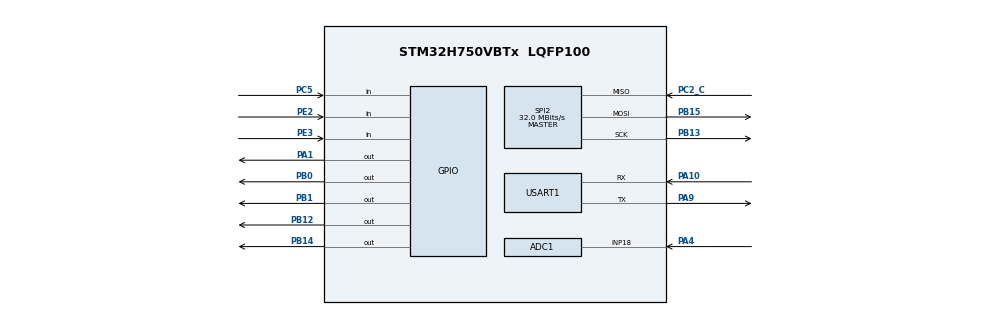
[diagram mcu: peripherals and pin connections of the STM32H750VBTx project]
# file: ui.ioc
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ADC1.Channel-3\#ChannelRegularConversion=ADC_CHANNEL_18
ADC1.ClockPrescaler=ADC_CLOCK_SYNC_PCLK_DIV4
ADC1.ContinuousConvMode=ENABLE
ADC1.ConversionDataManagement=ADC_CONVERSIONDATA_DMA_CIRCULAR
ADC1.NbrOfConversionFlag=1
ADC1.OffsetNumber-3\#ChannelRegularConversion=ADC_OFFSET_NONE
ADC1.OffsetSignedSaturation-3\#ChannelRegularConversion=DISABLE
ADC1.Rank-3\#ChannelRegularConversion=1
ADC1.Resolution=ADC_RESOLUTION_12B
ADC1.SamplingTime-3\#ChannelRegularConversion=ADC_SAMPLETIME_1CYCLE_5
ADC1.master=1
CORTEX_M7.default_mode_Activation=1
Dma.ADC1.3.Direction=DMA_PERIPH_TO_MEMORY
Dma.ADC1.3.EventEnable=DISABLE
Dma.ADC1.3.FIFOMode=DMA_FIFOMODE_DISABLE
Dma.ADC1.3.Instance=DMA1_Stream0
Dma.ADC1.3.MemDataAlignment=DMA_MDATAALIGN_WORD
Dma.ADC1.3.MemInc=DMA_MINC_ENABLE
Dma.ADC1.3.Mode=DMA_CIRCULAR
Dma.ADC1.3.PeriphDataAlignment=DMA_PDATAALIGN_WORD
Dma.ADC1.3.PeriphInc=DMA_PINC_DISABLE
Dma.ADC1.3.Polarity=HAL_DMAMUX_REQ_GEN_RISING
Dma.ADC1.3.Priority=DMA_PRIORITY_LOW
Dma.ADC1.3.RequestNumber=1
Dma.ADC1.3.SignalID=NONE
Dma.ADC1.3.SyncEnable=DISABLE
Dma.ADC1.3.SyncPolarity=HAL_DMAMUX_SYNC_NO_EVENT
Dma.ADC1.3.SyncRequestNumber=1
Dma.ADC1.3.SyncSignalID=NONE
Dma.Request0=SPI2_TX
Dma.Request1=USART1_RX
Dma.Request2=USART1_TX
Dma.Request3=ADC1
Dma.SPI2_TX.0.Direction=DMA_MEMORY_TO_PERIPH
Dma.SPI2_TX.0.EventEnable=DISABLE
Dma.SPI2_TX.0.FIFOMode=DMA_FIFOMODE_DISABLE
Dma.SPI2_TX.0.Instance=DMA2_Stream0
Dma.SPI2_TX.0.MemDataAlignment=DMA_MDATAALIGN_BYTE
Dma.SPI2_TX.0.MemInc=DMA_MINC_ENABLE
Dma.SPI2_TX.0.Mode=DMA_NORMAL
Dma.SPI2_TX.0.PeriphDataAlignment=DMA_PDATAALIGN_BYTE
Dma.SPI2_TX.0.PeriphInc=DMA_PINC_DISABLE
Dma.SPI2_TX.0.Polarity=HAL_DMAMUX_REQ_GEN_RISING
Dma.SPI2_TX.0.Priority=DMA_PRIORITY_LOW
Dma.SPI2_TX.0.RequestNumber=1
Dma.SPI2_TX.0.SignalID=NONE
Dma.SPI2_TX.0.SyncEnable=DISABLE
Dma.SPI2_TX.0.SyncPolarity=HAL_DMAMUX_SYNC_NO_EVENT
Dma.SPI2_TX.0.SyncRequestNumber=1
Dma.SPI2_TX.0.SyncSignalID=NONE
Dma.USART1_RX.1.Direction=DMA_PERIPH_TO_MEMORY
Dma.USART1_RX.1.EventEnable=DISABLE
Dma.USART1_RX.1.FIFOMode=DMA_FIFOMODE_DISABLE
Dma.USART1_RX.1.Instance=DMA1_Stream2
Dma.USART1_RX.1.MemDataAlignment=DMA_MDATAALIGN_BYTE
Dma.USART1_RX.1.MemInc=DMA_MINC_ENABLE
Dma.USART1_RX.1.Mode=DMA_NORMAL
Dma.USART1_RX.1.PeriphDataAlignment=DMA_PDATAALIGN_BYTE
Dma.USART1_RX.1.PeriphInc=DMA_PINC_DISABLE
Dma.USART1_RX.1.Polarity=HAL_DMAMUX_REQ_GEN_RISING
Dma.USART1_RX.1.Priority=DMA_PRIORITY_HIGH
Dma.USART1_RX.1.RequestNumber=1
Dma.USART1_RX.1.SignalID=NONE
Dma.USART1_RX.1.SyncEnable=DISABLE
Dma.USART1_RX.1.SyncPolarity=HAL_DMAMUX_SYNC_NO_EVENT
Dma.USART1_RX.1.SyncRequestNumber=1
Dma.USART1_RX.1.SyncSignalID=NONE
Dma.USART1_TX.2.Direction=DMA_MEMORY_TO_PERIPH
Dma.USART1_TX.2.EventEnable=DISABLE
Dma.USART1_TX.2.FIFOMode=DMA_FIFOMODE_DISABLE
Dma.USART1_TX.2.Instance=DMA1_Stream1
Dma.USART1_TX.2.MemDataAlignment=DMA_MDATAALIGN_BYTE
Dma.USART1_TX.2.MemInc=DMA_MINC_ENABLE
Dma.USART1_TX.2.Mode=DMA_NORMAL
Dma.USART1_TX.2.PeriphDataAlignment=DMA_PDATAALIGN_BYTE
Dma.USART1_TX.2.PeriphInc=DMA_PINC_DISABLE
Dma.USART1_TX.2.Polarity=HAL_DMAMUX_REQ_GEN_RISING
Dma.USART1_TX.2.Priority=DMA_PRIORITY_HIGH
Dma.USART1_TX.2.RequestNumber=1
Dma.USART1_TX.2.SignalID=NONE
Dma.USART1_TX.2.SyncEnable=DISABLE
Dma.USART1_TX.2.SyncPolarity=HAL_DMAMUX_SYNC_NO_EVENT
Dma.USART1_TX.2.SyncRequestNumber=1
Dma.USART1_TX.2.SyncSignalID=NONE
Mcu.Family=STM32H7
Mcu.Name=STM32H750VBTx
Mcu.Package=LQFP100
NVIC.DMA1_Stream0_IRQn=true\:1\:0\:true\:false\:true\:false\:true\:true
NVIC.DMA1_Stream1_IRQn=true\:1\:0\:true\:false\:true\:false\:true\:true
NVIC.DMA1_Stream2_IRQn=true\:1\:0\:true\:false\:true\:false\:true\:true
NVIC.DMA2_Stream0_IRQn=true\:1\:0\:true\:false\:true\:false\:true\:true
NVIC.PriorityGroup=NVIC_PRIORITYGROUP_4
NVIC.SPI2_IRQn=true\:0\:0\:false\:false\:true\:false\:true\:true
NVIC.TIM8_TRG_COM_TIM14_IRQn=true\:0\:0\:true\:false\:true\:true\:true\:true
NVIC.USART1_IRQn=true\:1\:0\:true\:false\:true\:true\:true\:true
PA1.GPIO_Speed=GPIO_SPEED_FREQ_VERY_HIGH
PA1.Signal=GPIO_Output
PA10.Mode=Asynchronous
PA10.Signal=USART1_RX
PA13\ (JTMS/SWDIO).Mode=Serial_Wire
PA13\ (JTMS/SWDIO).Signal=DEBUG_JTMS-SWDIO
PA14\ (JTCK/SWCLK).Mode=Serial_Wire
PA14\ (JTCK/SWCLK).Signal=DEBUG_JTCK-SWCLK
PA4.Signal=ADCx_INP18
PA9.Mode=Asynchronous
PA9.Signal=USART1_TX
PB0.GPIO_Speed=GPIO_SPEED_FREQ_VERY_HIGH
PB0.Signal=GPIO_Output
PB1.GPIO_Speed=GPIO_SPEED_FREQ_VERY_HIGH
PB1.Signal=GPIO_Output
PB12.GPIO_Speed=GPIO_SPEED_FREQ_VERY_HIGH
PB12.Signal=GPIO_Output
PB13.Mode=Full_Duplex_Master
PB13.Signal=SPI2_SCK
PB14.GPIO_Speed=GPIO_SPEED_FREQ_VERY_HIGH
PB14.Signal=GPIO_Output
PB15.Mode=Full_Duplex_Master
PB15.Signal=SPI2_MOSI
PC2_C.Mode=Full_Duplex_Master
PC2_C.Signal=SPI2_MISO
PC5.GPIO_PuPd=GPIO_PULLUP
PC5.Signal=GPIO_Input
PE2.GPIO_PuPd=GPIO_PULLUP
PE2.Signal=GPIO_Input
PE3.GPIO_PuPd=GPIO_PULLUP
PE3.Signal=GPIO_Input
PH0-OSC_IN\ (PH0).Mode=HSE-External-Oscillator
PH0-OSC_IN\ (PH0).Signal=RCC_OSC_IN
PH1-OSC_OUT\ (PH1).Mode=HSE-External-Oscillator
PH1-OSC_OUT\ (PH1).Signal=RCC_OSC_OUT
ProjectManager.HeapSize=0x200
ProjectManager.StackSize=0x2000
ProjectManager.TargetToolchain=STM32CubeIDE
RCC.ADCCLockSelection=RCC_ADCCLKSOURCE_CLKP
RCC.ADCFreq_Value=64000000
RCC.APB1Freq_Value=120000000
RCC.APB2Freq_Value=120000000
RCC.APB3Freq_Value=120000000
RCC.APB4Freq_Value=120000000
RCC.CortexFreq_Value=480000000
RCC.D1PPRE=RCC_APB3_DIV2
RCC.D2PPRE1=RCC_APB1_DIV2
RCC.D2PPRE2=RCC_APB2_DIV2
RCC.D3PPRE=RCC_APB4_DIV2
RCC.DIVM1=4
RCC.DIVM2=4
RCC.DIVN1=60
RCC.DIVN2=16
RCC.HCLKFreq_Value=240000000
RCC.HPRE=RCC_HCLK_DIV2
RCC.PLL2FRACN=0
RCC.PLL3FRACN=0
RCC.PLLFRACN=0
RCC.SPI123CLockSelection=RCC_SPI123CLKSOURCE_PLL2
RCC.SYSCLKFreq_VALUE=480000000
RCC.SYSCLKSource=RCC_SYSCLKSOURCE_PLLCLK
RCC.USBFreq_Value=480000000
SH.ADCx_INP18.0=ADC1_INP18,IN18-Single-Ended
SPI2.BaudRatePrescaler=SPI_BAUDRATEPRESCALER_4
SPI2.CLKPhase=SPI_PHASE_2EDGE
SPI2.CLKPolarity=SPI_POLARITY_HIGH
SPI2.CalculateBaudRate=32.0 MBits/s
SPI2.DataSize=SPI_DATASIZE_8BIT
SPI2.Direction=SPI_DIRECTION_2LINES
SPI2.Mode=SPI_MODE_MASTER
SPI2.VirtualType=VM_MASTER
TIM14.AutoReloadPreload=TIM_AUTORELOAD_PRELOAD_ENABLE
TIM14.Period=1000-1
TIM14.Prescaler=240-1
USART1.VirtualMode-Asynchronous=VM_ASYNC
VP_MEMORYMAP_VS_MEMORYMAP.Mode=CurAppReg
VP_TIM14_VS_ClockSourceINT.Mode=Enable_Timer
board=custom

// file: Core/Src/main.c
/* USER CODE BEGIN Header */
/**
  ******************************************************************************
  * @file           : main.c
  * @brief          : Main program body
  ******************************************************************************
  * @attention
  *
  * Copyright (c) 2025 STMicroelectronics.
  * All rights reserved.
  *
  * This software is licensed under terms that can be found in the LICENSE file
  * in the root directory of this software component.
  * If no LICENSE file comes with this software, it is provided AS-IS.
  *
  ******************************************************************************
  */
/* USER CODE END Header */
#include "main.h"
#include "adc.h"
#include "dma.h"
#include "memorymap.h"
#include "spi.h"
#include "tim.h"
#include "usart.h"
#include "gpio.h"

/* USER CODE BEGIN Includes */
#include "bsp_system.h"
/* USER CODE END Includes */

void SystemClock_Config(void);
static void MPU_Config(void);

int main(void)
{

  /* MPU Configuration--------------------------------------------------------*/
  MPU_Config();

  /* MCU Configuration--------------------------------------------------------*/

  /* Reset of all peripherals, Initializes the Flash interface and the Systick. */
  HAL_Init();

  /* Configure the system clock */
  SystemClock_Config();

  /* Initialize all configured peripherals */
  MX_GPIO_Init();
  MX_DMA_Init();
  MX_SPI2_Init();
  MX_TIM14_Init();
  MX_USART1_UART_Init();
  MX_ADC1_Init();
  /* USER CODE BEGIN 2 */
    loop();
  /* USER CODE END 2 */

  /* Infinite loop */
  while (1)
  {

  }
}

void SystemClock_Config(void)
{
  RCC_OscInitTypeDef RCC_OscInitStruct = {0};
  RCC_ClkInitTypeDef RCC_ClkInitStruct = {0};

  /** Supply configuration update enable
  */
  HAL_PWREx_ConfigSupply(PWR_LDO_SUPPLY);

  /** Configure the main internal regulator output voltage
  */
  __HAL_PWR_VOLTAGESCALING_CONFIG(PWR_REGULATOR_VOLTAGE_SCALE0);

  while(!__HAL_PWR_GET_FLAG(PWR_FLAG_VOSRDY)) {}

  /** Initializes the RCC Oscillators according to the specified parameters
  * in the RCC_OscInitTypeDef structure.
  */
  RCC_OscInitStruct.OscillatorType = RCC_OSCILLATORTYPE_HSI;
  RCC_OscInitStruct.HSIState = RCC_HSI_DIV1;
  RCC_OscInitStruct.HSICalibrationValue = RCC_HSICALIBRATION_DEFAULT;
  RCC_OscInitStruct.PLL.PLLState = RCC_PLL_ON;
  RCC_OscInitStruct.PLL.PLLSource = RCC_PLLSOURCE_HSI;
  RCC_OscInitStruct.PLL.PLLM = 4;
  RCC_OscInitStruct.PLL.PLLN = 60;
  RCC_OscInitStruct.PLL.PLLP = 2;
  RCC_OscInitStruct.PLL.PLLQ = 2;
  RCC_OscInitStruct.PLL.PLLR = 2;
  RCC_OscInitStruct.PLL.PLLRGE = RCC_PLL1VCIRANGE_3;
  RCC_OscInitStruct.PLL.PLLVCOSEL = RCC_PLL1VCOWIDE;
  RCC_OscInitStruct.PLL.PLLFRACN = 0;
  if (HAL_RCC_OscConfig(&RCC_OscInitStruct) != HAL_OK)
  {
    Error_Handler();
  }

  /** Initializes the CPU, AHB and APB buses clocks
  */
  RCC_ClkInitStruct.ClockType = RCC_CLOCKTYPE_HCLK|RCC_CLOCKTYPE_SYSCLK
                              |RCC_CLOCKTYPE_PCLK1|RCC_CLOCKTYPE_PCLK2
                              |RCC_CLOCKTYPE_D3PCLK1|RCC_CLOCKTYPE_D1PCLK1;
  RCC_ClkInitStruct.SYSCLKSource = RCC_SYSCLKSOURCE_PLLCLK;
  RCC_ClkInitStruct.SYSCLKDivider = RCC_SYSCLK_DIV1;
  RCC_ClkInitStruct.AHBCLKDivider = RCC_HCLK_DIV2;
  RCC_ClkInitStruct.APB3CLKDivider = RCC_APB3_DIV2;
  RCC_ClkInitStruct.APB1CLKDivider = RCC_APB1_DIV2;
  RCC_ClkInitStruct.APB2CLKDivider = RCC_APB2_DIV2;
  RCC_ClkInitStruct.APB4CLKDivider = RCC_APB4_DIV2;

  if (HAL_RCC_ClockConfig(&RCC_ClkInitStruct, FLASH_LATENCY_4) != HAL_OK)
  {
    Error_Handler();
  }
}

 /* MPU Configuration */

void MPU_Config(void)
{
  MPU_Region_InitTypeDef MPU_InitStruct = {0};

  /* Disables the MPU */
  HAL_MPU_Disable();

  /** Initializes and configures the Region and the memory to be protected
  */
  MPU_InitStruct.Enable = MPU_REGION_ENABLE;
  MPU_InitStruct.Number = MPU_REGION_NUMBER0;
  MPU_InitStruct.BaseAddress = 0x0;
  MPU_InitStruct.Size = MPU_REGION_SIZE_4GB;
  MPU_InitStruct.SubRegionDisable = 0x87;
  MPU_InitStruct.TypeExtField = MPU_TEX_LEVEL0;
  MPU_InitStruct.AccessPermission = MPU_REGION_NO_ACCESS;
  MPU_InitStruct.DisableExec = MPU_INSTRUCTION_ACCESS_DISABLE;
  MPU_InitStruct.IsShareable = MPU_ACCESS_SHAREABLE;
  MPU_InitStruct.IsCacheable = MPU_ACCESS_NOT_CACHEABLE;
  MPU_InitStruct.IsBufferable = MPU_ACCESS_NOT_BUFFERABLE;

  HAL_MPU_ConfigRegion(&MPU_InitStruct);
  /* Enables the MPU */
  HAL_MPU_Enable(MPU_PRIVILEGED_DEFAULT);

}

void Error_Handler(void)
{
  __disable_irq();
  while (1)
  {
  }
}
